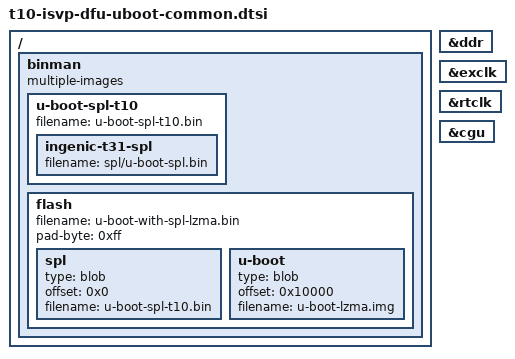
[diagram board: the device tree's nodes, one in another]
// SPDX-License-Identifier: GPL-2.0+
/*
 * Shared U-Boot overlay for the Ingenic ISVP-T10 DFU/USB-boot leaf DTs.
 * Each per-SKU <leaf>-u-boot.dtsi is a one-line include of this file.
 *
 * USB-boot is a TPL chain: the mask ROM uploads the cache-as-RAM TPL (its only
 * DM device is &ddr; the probe brings up PLL + DDR), the TPL returns into the
 * ROM's USB loop, and the ROM uploads U-Boot proper to DRAM. So the binman
 * flash image here is not used in the USB-boot flow (kept for a sensible `make`
 * artifact); thingino-dfu uploads tpl/u-boot-tpl.bin + u-boot.bin directly.
 *
 * &ddr is the only node tagged for the TPL phase (bootph-all); everything else
 * is bootph-pre-ram + bootph-some-ram (present pre-relocation in U-Boot proper,
 * absent from the minimal TPL - tagging the clock tree bootph-all would pull the
 * clk uclass into the TPL's OF_PLATDATA scan and fail it).
 */

/ {
	binman: binman {
		multiple-images;
	};
};

&binman {
	u-boot-spl-t10 {
		filename = "u-boot-spl-t10.bin";

		ingenic-t31-spl {
			filename = "spl/u-boot-spl.bin";
		};
	};

	flash {
		filename = "u-boot-with-spl-lzma.bin";
		pad-byte = <0xff>;

		spl {
			type = "blob";
			offset = <0x0>;
			filename = "u-boot-spl-t10.bin";
		};

		u-boot {
			type = "blob";
			offset = <0x10000>;
			filename = "u-boot-lzma.img";
		};
	};
};

&ddr { bootph-all; };		/* the TPL's only DM device */
&exclk { bootph-pre-ram; bootph-some-ram; };
&rtclk { bootph-pre-ram; bootph-some-ram; };
&cgu { bootph-pre-ram; bootph-some-ram; };
